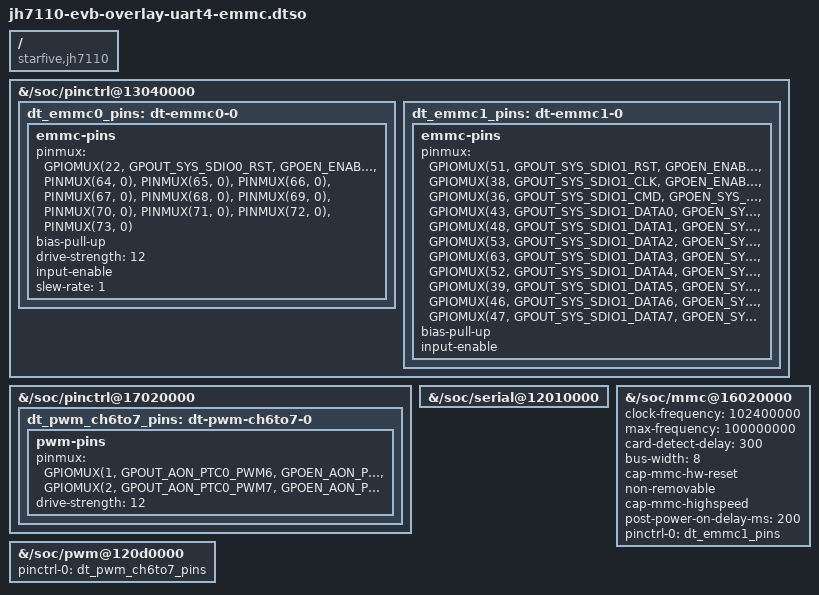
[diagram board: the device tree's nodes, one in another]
/dts-v1/;
/plugin/;
#include <dt-bindings/gpio/gpio.h>
#include "../jh7110-pinfunc.h"
/ {
	compatible = "starfive,jh7110";

	//sysgpio
	fragment@0 {
		target-path = "/soc/pinctrl@13040000";
		__overlay__ {
			dt_emmc0_pins: dt-emmc0-0 {
				emmc-pins {
					pinmux = <GPIOMUX(22, GPOUT_SYS_SDIO0_RST,
							      GPOEN_ENABLE,
							      GPI_NONE)>,
						 <PINMUX(64, 0)>,
						 <PINMUX(65, 0)>,
						 <PINMUX(66, 0)>,
						 <PINMUX(67, 0)>,
						 <PINMUX(68, 0)>,
						 <PINMUX(69, 0)>,
						 <PINMUX(70, 0)>,
						 <PINMUX(71, 0)>,
						 <PINMUX(72, 0)>,
						 <PINMUX(73, 0)>;
					bias-pull-up;
					drive-strength = <12>;
					input-enable;
					slew-rate = <1>;
				};
			};

			dt_emmc1_pins: dt-emmc1-0 {
				emmc-pins {
					pinmux = <GPIOMUX(51, GPOUT_SYS_SDIO1_RST,
							      GPOEN_ENABLE,
							      GPI_NONE)>,
						 <GPIOMUX(38, GPOUT_SYS_SDIO1_CLK,
							      GPOEN_ENABLE,
							      GPI_NONE)>,
						 <GPIOMUX(36, GPOUT_SYS_SDIO1_CMD,
							      GPOEN_SYS_SDIO1_CMD,
							      GPI_SYS_SDIO1_CMD)>,
						 <GPIOMUX(43, GPOUT_SYS_SDIO1_DATA0,
							      GPOEN_SYS_SDIO1_DATA0,
							      GPI_SYS_SDIO1_DATA0)>,
						 <GPIOMUX(48, GPOUT_SYS_SDIO1_DATA1,
							      GPOEN_SYS_SDIO1_DATA1,
							      GPI_SYS_SDIO1_DATA1)>,
						 <GPIOMUX(53, GPOUT_SYS_SDIO1_DATA2,
							      GPOEN_SYS_SDIO1_DATA2,
							      GPI_SYS_SDIO1_DATA2)>,
						 <GPIOMUX(63, GPOUT_SYS_SDIO1_DATA3,
							      GPOEN_SYS_SDIO1_DATA3,
							      GPI_SYS_SDIO1_DATA3)>,
						 <GPIOMUX(52, GPOUT_SYS_SDIO1_DATA4,
							      GPOEN_SYS_SDIO1_DATA4,
							      GPI_SYS_SDIO1_DATA4)>,
						 <GPIOMUX(39, GPOUT_SYS_SDIO1_DATA5,
							      GPOEN_SYS_SDIO1_DATA5,
							      GPI_SYS_SDIO1_DATA5)>,
						 <GPIOMUX(46, GPOUT_SYS_SDIO1_DATA6,
							      GPOEN_SYS_SDIO1_DATA6,
							      GPI_SYS_SDIO1_DATA6)>,
						 <GPIOMUX(47, GPOUT_SYS_SDIO1_DATA7,
							      GPOEN_SYS_SDIO1_DATA7,
							      GPI_SYS_SDIO1_DATA7)>;
					bias-pull-up;
					input-enable;
				};
			};
		};
	};

	//aongpio
	fragment@1 {
		target-path = "/soc/pinctrl@17020000";
		__overlay__ {
			dt_pwm_ch6to7_pins: dt-pwm-ch6to7-0 {
				pwm-pins {
					pinmux = <GPIOMUX(1, GPOUT_AON_PTC0_PWM6, /* PAD_RGPIO0 */
							     GPOEN_AON_PTC0_OE_N_6,
							     GPI_NONE)>,
						 <GPIOMUX(2, GPOUT_AON_PTC0_PWM7, /* PAD_RGPIO1 */
							     GPOEN_AON_PTC0_OE_N_7,
							     GPI_NONE)>;
					drive-strength = <12>;
				};
			};
		};
	};

	//uart4
	fragment@2 {
		target-path = "/soc/serial@12010000";
		__overlay__ {
			status = "okay";
		};
	};

	//mmc1
	fragment@3 {
		target-path = "/soc/mmc@16020000";
		__overlay__ {
			clock-frequency = <102400000>;
			max-frequency = <100000000>;
			card-detect-delay = <300>;
			bus-width = <8>;
			cap-mmc-hw-reset;
			non-removable;
			cap-mmc-highspeed;
			post-power-on-delay-ms = <200>;
			pinctrl-names = "default";
			pinctrl-0 = <&dt_emmc1_pins>;
			status = "okay";
		};
	};

	//ptc
	fragment@4 {
		target-path = "/soc/pwm@120d0000";
		__overlay__ {
			pinctrl-names = "default";
			pinctrl-0 = <&dt_pwm_ch6to7_pins>;
			status = "okay";
		};
	};
};

